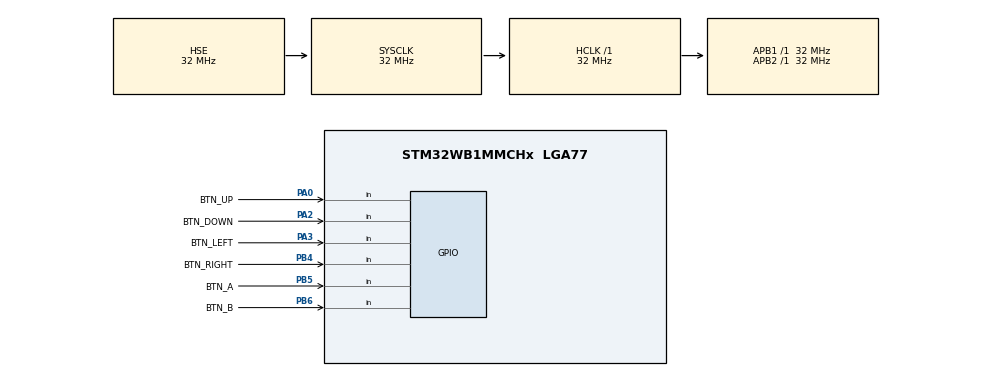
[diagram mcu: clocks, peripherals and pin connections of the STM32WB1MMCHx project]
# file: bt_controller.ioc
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Mcu.Family=STM32WB
Mcu.Name=STM32WB1MMCHx
Mcu.Package=LGA77
NVIC.HSEM_IRQn=true\:0\:0\:false\:false\:true\:false\:true\:true
NVIC.IPCC_C1_RX_IRQn=true\:0\:0\:false\:false\:true\:true\:true\:true
NVIC.IPCC_C1_TX_IRQn=true\:0\:0\:false\:false\:true\:true\:true\:true
NVIC.LPTIM2_IRQn=true\:5\:0\:true\:false\:true\:true\:true\:true
NVIC.PriorityGroup=NVIC_PRIORITYGROUP_4
NVIC.RTC_WKUP_IRQn=true\:3\:0\:true\:false\:true\:true\:true\:true
PA0.GPIO_Label=BTN_UP
PA0.GPIO_PuPd=GPIO_PULLUP
PA0.Signal=GPIO_Input
PA13.Mode=Serial_Wire
PA13.Signal=SYS_JTMS-SWDIO
PA14.Mode=Serial_Wire
PA14.Signal=SYS_JTCK-SWCLK
PA2.GPIO_Label=BTN_DOWN
PA2.GPIO_PuPd=GPIO_PULLUP
PA2.Signal=GPIO_Input
PA3.GPIO_Label=BTN_LEFT
PA3.GPIO_PuPd=GPIO_PULLUP
PA3.Signal=GPIO_Input
PB4.GPIO_Label=BTN_RIGHT
PB4.GPIO_PuPd=GPIO_PULLUP
PB4.Signal=GPIO_Input
PB5.GPIO_Label=BTN_A
PB5.GPIO_PuPd=GPIO_PULLUP
PB5.Signal=GPIO_Input
PB6.GPIO_Label=BTN_B
PB6.GPIO_PuPd=GPIO_PULLUP
PB6.Signal=GPIO_Input
ProjectManager.HeapSize=0x200
ProjectManager.StackSize=0x400
ProjectManager.TargetToolchain=STM32CubeIDE
RCC.AHBFreq_Value=32000000
RCC.APB1Freq_Value=32000000
RCC.APB1TimFreq_Value=32000000
RCC.APB2Freq_Value=32000000
RCC.APB2TimFreq_Value=32000000
RCC.APB3Freq_Value=16000000
RCC.CortexFreq_Value=32000000
RCC.HCLKFreq_Value=32000000
RCC.HSE_VALUE=32000000
RCC.HSI_VALUE=16000000
RCC.LPTIM2CLockSelection=RCC_LPTIM2CLKSOURCE_LSE
RCC.RFWKPClockSelection=RCC_RFWKPCLKSOURCE_LSE
RCC.RTCClockSelection=RCC_RTCCLKSOURCE_LSE
RCC.SMPSCLockSelectionVirtual=RCC_SMPSCLKSOURCE_HSE
RCC.SMPSDivider=4
RCC.SYSCLKFreq_VALUE=32000000
RCC.SYSCLKSource=RCC_SYSCLKSOURCE_HSE
RCC.VCOOutputFreq_Value=32000000
STM32_WPAN.AD_TYPE_COMPLETE_LOCAL_NAME=GAMEPAD
STM32_WPAN.AD_TYPE_COMPLETE_LOCAL_NAME_LENGTH=8
STM32_WPAN.CFG_BLE_NUM_LINK=1
STM32_WPAN.CFG_GAP_DEVICE_NAME=GAMEPAD
STM32_WPAN.CFG_GAP_DEVICE_NAME_LENGTH=7
STM32_WPAN.CFG_LPM_SUPPORTED=1
STM32_WPAN.CFG_LSCLK_LSE=0
STM32_WPAN.CUSTOM_P2P_SERVER=Disabled
STM32_WPAN.CUSTOM_TEMPLATE=Enabled
STM32_WPAN.GAP_PERIPHERAL_ROLE=1
STM32_WPAN.INCLUDE_AD_TYPE_COMPLETE_LOCAL_NAME=1
STM32_WPAN.NUMBER_OF_SERVICES=1
STM32_WPAN.SERVICE1_CHAR1_GATT_NOTIFY_READ_REQ_AND_WAIT_FOR_APPL_RESP=\ 
STM32_WPAN.SERVICE1_CHAR1_GATT_NOTIFY_WRITE_REQ_AND_WAIT_FOR_APPL_RESP=\ 
STM32_WPAN.SERVICE1_CHAR1_LONG_NAME=Button_State
STM32_WPAN.SERVICE1_CHAR1_PROP_NOTIFY=CHAR_PROP_NOTIFY
STM32_WPAN.SERVICE1_CHAR1_PROP_READ=CHAR_PROP_READ
STM32_WPAN.SERVICE1_CHAR1_SHORT_NAME=BTN_STATE
STM32_WPAN.SERVICE1_CHAR1_UUID=A1 02
STM32_WPAN.SERVICE1_LONG_NAME=Controller_Input
STM32_WPAN.SERVICE1_SHORT_NAME=CTRL_INPUT
STM32_WPAN.SERVICE1_UUID=A1 01
VP_HSEM_VS_HSEM.Mode=HSEM_Activate
VP_IPCC_VS_IPCC.Mode=IPCC_Activate
VP_LPTIM2_VS_LPTIM_counterModeInternalClock.Mode=Counts__internal_clock_event_00
VP_MEMORYMAP_VS_MEMORYMAP.Mode=CurAppReg
VP_RCC_V_OSC32_IN.Mode=LSE-External-Clock-Source
VP_RCC_V_OSC_IN.Mode=HSE-External-Clock-Source
VP_RF_VS_RF.Mode=RF_Activate
VP_RTC_VS_RTC_Activate.Mode=RTC_Enabled
VP_RTC_VS_RTC_WakeUp_intern.Mode=WakeUp
VP_SEQUENCER_VS_SEQUENCER.Mode=SEQUENCER_Enabled
VP_STM32_WPAN_VS_BLE_HOST.Mode=STM32_WPAN_Enabled
VP_TINY_LPM_VS_TINY_LPM.Mode=TINY_LPM_Enabled
board=custom

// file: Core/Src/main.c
/* USER CODE BEGIN Header */
/**
  ******************************************************************************
  * @file           : main.c
  * @brief          : Main program body
  ******************************************************************************
  * @attention
  *
  * Copyright (c) 2026 STMicroelectronics.
  * All rights reserved.
  *
  * This software is licensed under terms that can be found in the LICENSE file
  * in the root directory of this software component.
  * If no LICENSE file comes with this software, it is provided AS-IS.
  *
  ******************************************************************************
  */
/* USER CODE END Header */
#include "main.h"

/* USER CODE BEGIN Includes */

#include "input.h"
#include "error.h"
#include "custom_app.h"

/* USER CODE END Includes */

IPCC_HandleTypeDef hipcc;

LPTIM_HandleTypeDef hlptim2;

RTC_HandleTypeDef hrtc;

/* USER CODE BEGIN PV */

static uint8_t input_refresh_ticks;

/* USER CODE END PV */

void SystemClock_Config(void);
void PeriphCommonClock_Config(void);
static void MX_GPIO_Init(void);
static void MX_IPCC_Init(void);
static void MX_RTC_Init(void);
static void MX_LPTIM2_Init(void);
static void MX_RF_Init(void);

int main(void)
{

  /* MCU Configuration--------------------------------------------------------*/

  /* Reset of all peripherals, Initializes the Flash interface and the Systick. */
  HAL_Init();
  /* Config code for STM32_WPAN (HSE Tuning must be done before system clock configuration) */
  MX_APPE_Config();

  /* Configure the system clock */
  SystemClock_Config();

  /* Configure the peripherals common clocks */
  PeriphCommonClock_Config();

  /* IPCC initialisation */
  MX_IPCC_Init();

  /* Initialize all configured peripherals */
  MX_GPIO_Init();
  MX_RTC_Init();
  MX_LPTIM2_Init();
  MX_RF_Init();

  /* Init code for STM32_WPAN */
  MX_APPE_Init();

  /* Infinite loop */
  while (1)
  {
    MX_APPE_Process();

  }
}

void SystemClock_Config(void)
{
  RCC_OscInitTypeDef RCC_OscInitStruct = {0};
  RCC_ClkInitTypeDef RCC_ClkInitStruct = {0};

  /** Configure LSE Drive Capability
  */
  HAL_PWR_EnableBkUpAccess();
  __HAL_RCC_LSEDRIVE_CONFIG(RCC_LSEDRIVE_MEDIUMHIGH);

  /** Initializes the RCC Oscillators according to the specified parameters
  * in the RCC_OscInitTypeDef structure.
  */
  RCC_OscInitStruct.OscillatorType = RCC_OSCILLATORTYPE_HSI|RCC_OSCILLATORTYPE_HSE
                              |RCC_OSCILLATORTYPE_LSE;
  RCC_OscInitStruct.HSEState = RCC_HSE_ON;
  RCC_OscInitStruct.LSEState = RCC_LSE_ON;
  RCC_OscInitStruct.HSIState = RCC_HSI_ON;
  RCC_OscInitStruct.HSICalibrationValue = RCC_HSICALIBRATION_DEFAULT;
  RCC_OscInitStruct.PLL.PLLState = RCC_PLL_NONE;
  if (HAL_RCC_OscConfig(&RCC_OscInitStruct) != HAL_OK)
  {
    Error_Handler();
  }

  /** Configure the SYSCLKSource, HCLK, PCLK1 and PCLK2 clocks dividers
  */
  RCC_ClkInitStruct.ClockType = RCC_CLOCKTYPE_HCLK4|RCC_CLOCKTYPE_HCLK2
                              |RCC_CLOCKTYPE_HCLK|RCC_CLOCKTYPE_SYSCLK
                              |RCC_CLOCKTYPE_PCLK1|RCC_CLOCKTYPE_PCLK2;
  RCC_ClkInitStruct.SYSCLKSource = RCC_SYSCLKSOURCE_HSE;
  RCC_ClkInitStruct.AHBCLKDivider = RCC_SYSCLK_DIV1;
  RCC_ClkInitStruct.APB1CLKDivider = RCC_HCLK_DIV1;
  RCC_ClkInitStruct.APB2CLKDivider = RCC_HCLK_DIV1;
  RCC_ClkInitStruct.AHBCLK2Divider = RCC_SYSCLK_DIV1;
  RCC_ClkInitStruct.AHBCLK4Divider = RCC_SYSCLK_DIV1;

  if (HAL_RCC_ClockConfig(&RCC_ClkInitStruct, FLASH_LATENCY_1) != HAL_OK)
  {
    Error_Handler();
  }
}

void PeriphCommonClock_Config(void)
{
  RCC_PeriphCLKInitTypeDef PeriphClkInitStruct = {0};

  /** Initializes the peripherals clock
  */
  PeriphClkInitStruct.PeriphClockSelection = RCC_PERIPHCLK_SMPS|RCC_PERIPHCLK_RFWAKEUP;
  PeriphClkInitStruct.RFWakeUpClockSelection = RCC_RFWKPCLKSOURCE_LSE;
  PeriphClkInitStruct.SmpsClockSelection = RCC_SMPSCLKSOURCE_HSE;
  PeriphClkInitStruct.SmpsDivSelection = RCC_SMPSCLKDIV_RANGE1;

  if (HAL_RCCEx_PeriphCLKConfig(&PeriphClkInitStruct) != HAL_OK)
  {
    Error_Handler();
  }
}

static void MX_IPCC_Init(void)
{

  hipcc.Instance = IPCC;
  if (HAL_IPCC_Init(&hipcc) != HAL_OK)
  {
    Error_Handler();
  }

}

static void MX_LPTIM2_Init(void)
{

  hlptim2.Instance = LPTIM2;
  hlptim2.Init.Clock.Source = LPTIM_CLOCKSOURCE_APBCLOCK_LPOSC;
  hlptim2.Init.Clock.Prescaler = LPTIM_PRESCALER_DIV1;
  hlptim2.Init.Trigger.Source = LPTIM_TRIGSOURCE_SOFTWARE;
  hlptim2.Init.OutputPolarity = LPTIM_OUTPUTPOLARITY_HIGH;
  hlptim2.Init.UpdateMode = LPTIM_UPDATE_IMMEDIATE;
  hlptim2.Init.CounterSource = LPTIM_COUNTERSOURCE_INTERNAL;
  hlptim2.Init.Input1Source = LPTIM_INPUT1SOURCE_GPIO;
  hlptim2.Init.Input2Source = LPTIM_INPUT2SOURCE_GPIO;
  if (HAL_LPTIM_Init(&hlptim2) != HAL_OK)
  {
    Error_Handler();
  }

}

static void MX_RF_Init(void)
{

}

static void MX_RTC_Init(void)
{

  /** Initialize RTC Only
  */
  hrtc.Instance = RTC;
  hrtc.Init.HourFormat = RTC_HOURFORMAT_24;
  hrtc.Init.AsynchPrediv = CFG_RTC_ASYNCH_PRESCALER;
  hrtc.Init.SynchPrediv = CFG_RTC_SYNCH_PRESCALER;
  hrtc.Init.OutPut = RTC_OUTPUT_DISABLE;
  hrtc.Init.OutPutPolarity = RTC_OUTPUT_POLARITY_HIGH;
  hrtc.Init.OutPutRemap = RTC_OUTPUT_REMAP_NONE;
  if (HAL_RTC_Init(&hrtc) != HAL_OK)
  {
    Error_Handler();
  }

  /** Enable the WakeUp
  */
  if (HAL_RTCEx_SetWakeUpTimer_IT(&hrtc, 0, RTC_WAKEUPCLOCK_RTCCLK_DIV16) != HAL_OK)
  {
    Error_Handler();
  }

}

static void MX_GPIO_Init(void)
{
  GPIO_InitTypeDef GPIO_InitStruct = {0};

  /* GPIO Ports Clock Enable */
  __HAL_RCC_GPIOA_CLK_ENABLE();
  __HAL_RCC_GPIOB_CLK_ENABLE();

  /*Configure GPIO pins : BTN_DOWN_Pin BTN_LEFT_Pin BTN_UP_Pin */
  GPIO_InitStruct.Pin = BTN_DOWN_Pin|BTN_LEFT_Pin|BTN_UP_Pin;
  GPIO_InitStruct.Mode = GPIO_MODE_INPUT;
  GPIO_InitStruct.Pull = GPIO_PULLUP;
  HAL_GPIO_Init(GPIOA, &GPIO_InitStruct);

  /*Configure GPIO pins : BTN_A_Pin BTN_B_Pin BTN_RIGHT_Pin */
  GPIO_InitStruct.Pin = BTN_A_Pin|BTN_B_Pin|BTN_RIGHT_Pin;
  GPIO_InitStruct.Mode = GPIO_MODE_INPUT;
  GPIO_InitStruct.Pull = GPIO_PULLUP;
  HAL_GPIO_Init(GPIOB, &GPIO_InitStruct);

}

/* USER CODE BEGIN 4 */

void HAL_LPTIM_AutoReloadMatchCallback(LPTIM_HandleTypeDef *hlptim)
{
	if (hlptim->Instance == LPTIM2) {
		const InputButtons previous = input_get();

		input_sample();

		input_refresh_ticks++;

		if (input_refresh_ticks >= 20U) {
			input_refresh_ticks = 0U;
		}

		if (input_get() != previous || input_refresh_ticks == 0U) {
			Custom_APP_RequestInputUpdate();
		}
	}
}

/* USER CODE END 4 */

void Error_Handler(void)
{
  /* USER CODE BEGIN Error_Handler_Debug */

  error_fatal();

  /* USER CODE END Error_Handler_Debug */
}
